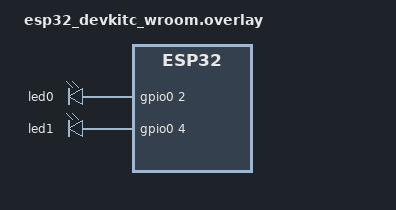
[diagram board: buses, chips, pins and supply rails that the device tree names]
/ {
    aliases {
        my-led = &led0;
        my-ext-led = &led1;
    };

    leds {
        compatible = "gpio-leds";
        led0: d2 {
            gpios = <&gpio0 2 GPIO_ACTIVE_HIGH>;
        };
        led1: d4 {
            gpios = <&gpio0 4 GPIO_ACTIVE_HIGH>;
        };
    };
};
